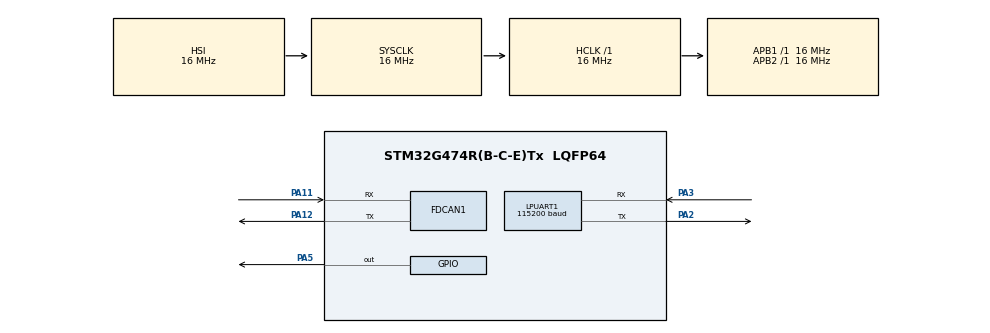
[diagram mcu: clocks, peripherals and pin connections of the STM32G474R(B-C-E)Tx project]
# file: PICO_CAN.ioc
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FDCAN1.AutoRetransmission=DISABLE
FDCAN1.CalculateBaudRateNominal=1000000
FDCAN1.CalculateTimeQuantumNominal=62.5
FDCAN1.ClockDivider=FDCAN_CLOCK_DIV1
FDCAN1.DataPrescaler=1
FDCAN1.DataSyncJumpWidth=1
FDCAN1.DataTimeSeg1=1
FDCAN1.DataTimeSeg2=1
FDCAN1.ExtFiltersNbr=0
FDCAN1.FrameFormat=FDCAN_FRAME_CLASSIC
FDCAN1.Mode=FDCAN_MODE_INTERNAL_LOOPBACK
FDCAN1.NominalPrescaler=1
FDCAN1.NominalSyncJumpWidth=2
FDCAN1.NominalTimeSeg1=13
FDCAN1.NominalTimeSeg2=2
FDCAN1.ProtocolException=DISABLE
FDCAN1.StdFiltersNbr=1
FDCAN1.TransmitPause=DISABLE
FDCAN1.TxFifoQueueMode=FDCAN_TX_FIFO_OPERATION
LPUART1.BaudRate=115200
Mcu.Family=STM32G4
Mcu.Name=STM32G474R(B-C-E)Tx
Mcu.Package=LQFP64
NVIC.FDCAN1_IT0_IRQn=true\:1\:0\:false\:false\:true\:true\:true\:true
NVIC.PriorityGroup=NVIC_PRIORITYGROUP_4
PA11.Mode=FDCAN_Activate
PA11.Signal=FDCAN1_RX
PA12.Mode=FDCAN_Activate
PA12.Signal=FDCAN1_TX
PA13.Mode=Serial_Wire
PA13.Signal=SYS_JTMS-SWDIO
PA14.Mode=Serial_Wire
PA14.Signal=SYS_JTCK-SWCLK
PA2.Mode=Asynchronous
PA2.Signal=LPUART1_TX
PA3.Mode=Asynchronous
PA3.Signal=LPUART1_RX
PA5.Signal=GPIO_Output
ProjectManager.HeapSize=0x200
ProjectManager.StackSize=0x1000
ProjectManager.TargetToolchain=CMake
RCC.AHBFreq_Value=16000000
RCC.APB1Freq_Value=16000000
RCC.APB1TimFreq_Value=16000000
RCC.APB2Freq_Value=16000000
RCC.APB2TimFreq_Value=16000000
RCC.CortexFreq_Value=16000000
RCC.EXTERNAL_CLOCK_VALUE=12288000
RCC.HCLKFreq_Value=16000000
RCC.HSE_VALUE=8000000
RCC.HSI48_VALUE=48000000
RCC.HSI_VALUE=16000000
RCC.LSE_VALUE=32768
RCC.SYSCLKFreq_VALUE=16000000
RCC.USBFreq_Value=64000000
RCC.VCOOutputFreq_Value=128000000
board=custom

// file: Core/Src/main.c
/* USER CODE BEGIN Header */
/**
  ******************************************************************************
  * @file           : main.c
  * @brief          : Main program body
  ******************************************************************************
  * @attention
  *
  * Copyright (c) 2026 STMicroelectronics.
  * All rights reserved.
  *
  * This software is licensed under terms that can be found in the LICENSE file
  * in the root directory of this software component.
  * If no LICENSE file comes with this software, it is provided AS-IS.
  *
  ******************************************************************************
  */
/* USER CODE END Header */
#include "main.h"
#include "fdcan.h"
#include "usart.h"
#include "gpio.h"

/* USER CODE BEGIN Includes */
#include "can_bringup.h"

/* USER CODE END Includes */

void SystemClock_Config(void);

int main(void)
{

  /* MCU Configuration--------------------------------------------------------*/

  /* Reset of all peripherals, Initializes the Flash interface and the Systick. */
  HAL_Init();

  /* Configure the system clock */
  SystemClock_Config();

  /* Initialize all configured peripherals */
  MX_GPIO_Init();
  MX_LPUART1_UART_Init();
  MX_FDCAN1_Init();
  /* USER CODE BEGIN 2 */
  CanTest_Init(&hfdcan1, &hlpuart1);

  /* USER CODE END 2 */

  /* Infinite loop */
  while (1)
  {

    /* USER CODE BEGIN 3 */
    CanTest_Step();
  }
  /* USER CODE END 3 */
}

void SystemClock_Config(void)
{
  RCC_OscInitTypeDef RCC_OscInitStruct = {0};
  RCC_ClkInitTypeDef RCC_ClkInitStruct = {0};

  /** Configure the main internal regulator output voltage
  */
  HAL_PWREx_ControlVoltageScaling(PWR_REGULATOR_VOLTAGE_SCALE1);

  /** Initializes the RCC Oscillators according to the specified parameters
  * in the RCC_OscInitTypeDef structure.
  */
  RCC_OscInitStruct.OscillatorType = RCC_OSCILLATORTYPE_HSI;
  RCC_OscInitStruct.HSIState = RCC_HSI_ON;
  RCC_OscInitStruct.HSICalibrationValue = RCC_HSICALIBRATION_DEFAULT;
  RCC_OscInitStruct.PLL.PLLState = RCC_PLL_NONE;
  if (HAL_RCC_OscConfig(&RCC_OscInitStruct) != HAL_OK)
  {
    Error_Handler();
  }

  /** Initializes the CPU, AHB and APB buses clocks
  */
  RCC_ClkInitStruct.ClockType = RCC_CLOCKTYPE_HCLK|RCC_CLOCKTYPE_SYSCLK
                              |RCC_CLOCKTYPE_PCLK1|RCC_CLOCKTYPE_PCLK2;
  RCC_ClkInitStruct.SYSCLKSource = RCC_SYSCLKSOURCE_HSI;
  RCC_ClkInitStruct.AHBCLKDivider = RCC_SYSCLK_DIV1;
  RCC_ClkInitStruct.APB1CLKDivider = RCC_HCLK_DIV1;
  RCC_ClkInitStruct.APB2CLKDivider = RCC_HCLK_DIV1;

  if (HAL_RCC_ClockConfig(&RCC_ClkInitStruct, FLASH_LATENCY_0) != HAL_OK)
  {
    Error_Handler();
  }
}

void Error_Handler(void)
{
  __disable_irq();
  while (1)
  {
  }
}
